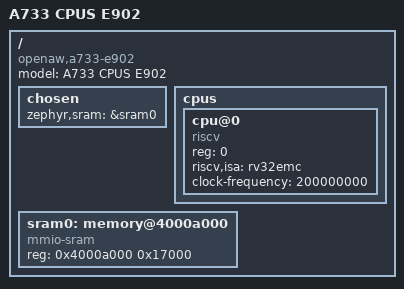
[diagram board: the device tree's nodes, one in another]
/dts-v1/;
/ {
 #address-cells = <1>;
 #size-cells = <1>;
 model = "A733 CPUS E902";
 compatible = "openaw,a733-e902";
 chosen { zephyr,sram = &sram0; };
 cpus {
  #address-cells = <1>;
  #size-cells = <0>;
  cpu@0 { device_type = "cpu"; compatible = "riscv"; reg = <0>; riscv,isa = "rv32emc"; clock-frequency = <200000000>; };
 };
 sram0: memory@4000a000 { device_type = "memory"; compatible = "mmio-sram"; reg = <0x4000a000 0x17000>; };
};
